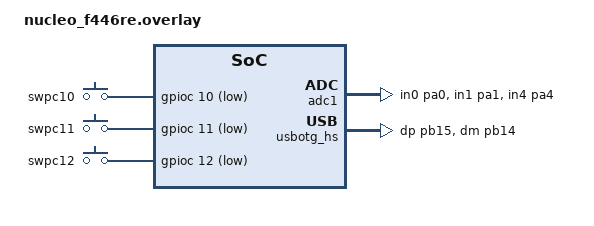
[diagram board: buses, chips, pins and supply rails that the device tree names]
/ {
	chosen {
		zephyr,canbus = &can2;
		zephyr,spi = &spi1;
		zephyr,adc = &adc1;
		zephyr,usbfunc = &usbotg_hs;
	};

	gpio_keys {
		compatible = "gpio-keys";
		user_button_0: swpc10 {
			gpios = <&gpioc 10 GPIO_ACTIVE_LOW>;
			label = "swpc10";
			zephyr,code = <INPUT_KEY_1>;
		};
		user_button_1: swpc11 {
			gpios = <&gpioc 11 GPIO_ACTIVE_LOW>;
			label = "swpc11";
			zephyr,code = <INPUT_KEY_2>;
		};
		user_button_2: swpc12 {
			gpios = <&gpioc 12 GPIO_ACTIVE_LOW>;
			label = "swpc12";
			zephyr,code = <INPUT_KEY_3>;
		};
	};

};

&adc1 {
	pinctrl-0 = <&adc1_in0_pa0 &adc1_in1_pa1 &adc1_in4_pa4 >;
	pinctrl-names = "default";
	st,adc-clock-source = <SYNC>;
	st,adc-prescaler = <2>;
	status = "okay";
};

&usbotg_hs {
	pinctrl-0 = <&usb_otg_hs_dp_pb15 &usb_otg_hs_dm_pb14 >;
	pinctrl-names = "default";
	status = "okay";

	cdc_acm_uart0 {
		compatible = "zephyr,cdc-acm-uart";
	};
};
